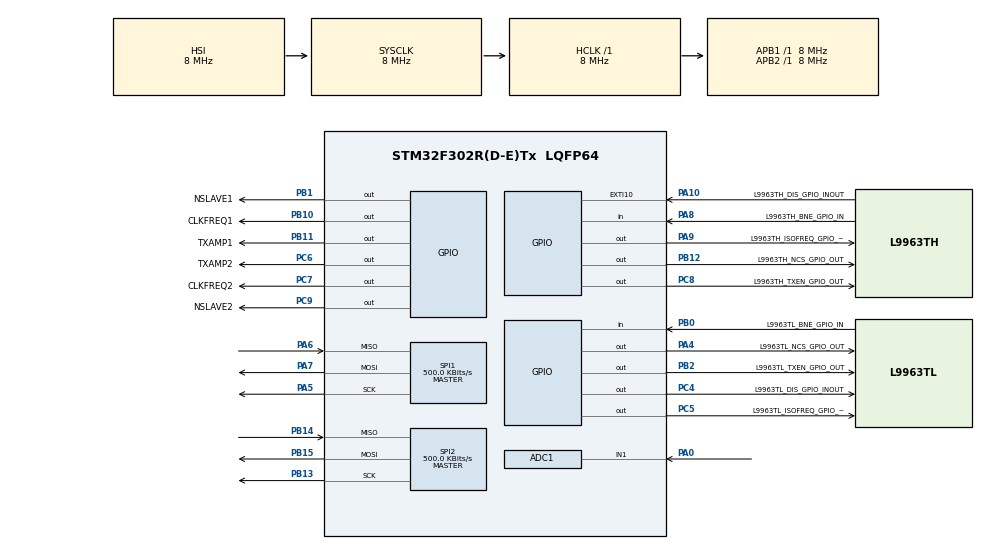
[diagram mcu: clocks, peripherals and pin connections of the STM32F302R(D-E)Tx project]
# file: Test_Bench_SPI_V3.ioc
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ADC1.Channel-0\#ChannelRegularConversion=ADC_CHANNEL_1
ADC1.NbrOfConversionFlag=1
ADC1.Offset-0\#ChannelRegularConversion=0
ADC1.OffsetNumber-0\#ChannelRegularConversion=ADC_OFFSET_NONE
ADC1.Rank-0\#ChannelRegularConversion=1
ADC1.SamplingTime-0\#ChannelRegularConversion=ADC_SAMPLETIME_1CYCLE_5
ADC1.SamplingTimeOPAMP-0\#ChannelRegularConversion=ADC_SAMPLETIME_4CYCLES_5
ADC1.master=1
Mcu.Family=STM32F3
Mcu.Name=STM32F302R(D-E)Tx
Mcu.Package=LQFP64
NVIC.PriorityGroup=NVIC_PRIORITYGROUP_4
PA0.Mode=IN1-Single-Ended
PA0.Signal=ADC1_IN1
PA10.GPIO_Label=L9963TH_DIS_GPIO_INOUT
PA10.Signal=GPXTI10
PA13.Mode=Serial_Wire
PA13.Signal=SYS_JTMS-SWDIO
PA14.Mode=Serial_Wire
PA14.Signal=SYS_JTCK-SWCLK
PA4.GPIO_Label=L9963TL_NCS_GPIO_OUT
PA4.Signal=GPIO_Output
PA5.Mode=Full_Duplex_Master
PA5.Signal=SPI1_SCK
PA6.Mode=Full_Duplex_Master
PA6.Signal=SPI1_MISO
PA7.Mode=Full_Duplex_Master
PA7.Signal=SPI1_MOSI
PA8.GPIO_Label=L9963TH_BNE_GPIO_IN
PA8.Signal=GPIO_Input
PA9.GPIO_Label=L9963TH_ISOFREQ_GPIO_OUT
PA9.Signal=GPIO_Output
PB0.GPIO_Label=L9963TL_BNE_GPIO_IN
PB0.Signal=GPIO_Input
PB1.GPIO_Label=NSLAVE1
PB1.Signal=GPIO_Output
PB10.GPIO_Label=CLKFREQ1
PB10.Signal=GPIO_Output
PB11.GPIO_Label=TXAMP1
PB11.Signal=GPIO_Output
PB12.GPIO_Label=L9963TH_NCS_GPIO_OUT
PB12.Signal=GPIO_Output
PB13.Mode=Full_Duplex_Master
PB13.Signal=SPI2_SCK
PB14.Mode=Full_Duplex_Master
PB14.Signal=SPI2_MISO
PB15.Mode=Full_Duplex_Master
PB15.Signal=SPI2_MOSI
PB2.GPIO_Label=L9963TL_TXEN_GPIO_OUT
PB2.Signal=GPIO_Output
PC4.GPIO_Label=L9963TL_DIS_GPIO_INOUT
PC4.Signal=GPIO_Output
PC5.GPIO_Label=L9963TL_ISOFREQ_GPIO_OUT
PC5.Signal=GPIO_Output
PC6.GPIO_Label=TXAMP2
PC6.Signal=GPIO_Output
PC7.GPIO_Label=CLKFREQ2
PC7.Signal=GPIO_Output
PC8.GPIO_Label=L9963TH_TXEN_GPIO_OUT
PC8.Signal=GPIO_Output
PC9.GPIO_Label=NSLAVE2
PC9.Signal=GPIO_Output
PF0-OSC_IN.Mode=HSE-External-Oscillator
PF0-OSC_IN.Signal=RCC_OSC_IN
PF1-OSC_OUT.Mode=HSE-External-Oscillator
PF1-OSC_OUT.Signal=RCC_OSC_OUT
ProjectManager.HeapSize=0x200
ProjectManager.StackSize=0x400
ProjectManager.TargetToolchain=STM32CubeIDE
RCC.AHBFreq_Value=8000000
RCC.APB1Freq_Value=8000000
RCC.APB2Freq_Value=8000000
RCC.CortexFreq_Value=8000000
RCC.HSE_VALUE=8000000
RCC.HSI_VALUE=8000000
RCC.LSE_VALUE=32768
RCC.PLLMUL=RCC_PLL_MUL4
RCC.SYSCLKFreq_VALUE=8000000
RCC.USBFreq_Value=16000000
SPI1.BaudRatePrescaler=SPI_BAUDRATEPRESCALER_16
SPI1.CalculateBaudRate=500.0 KBits/s
SPI1.DataSize=SPI_DATASIZE_8BIT
SPI1.Direction=SPI_DIRECTION_2LINES
SPI1.Mode=SPI_MODE_MASTER
SPI1.VirtualType=VM_MASTER
SPI2.BaudRatePrescaler=SPI_BAUDRATEPRESCALER_16
SPI2.CalculateBaudRate=500.0 KBits/s
SPI2.DataSize=SPI_DATASIZE_8BIT
SPI2.Direction=SPI_DIRECTION_2LINES
SPI2.Mode=SPI_MODE_MASTER
SPI2.VirtualType=VM_MASTER
board=custom

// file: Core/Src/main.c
/* USER CODE BEGIN Header */
/**
  ******************************************************************************
  * @file           : main.c
  * @brief          : Main program body
  ******************************************************************************
  * @attention
  *
  * Copyright (c) 2025 STMicroelectronics.
  * All rights reserved.
  *
  * This software is licensed under terms that can be found in the LICENSE file
  * in the root directory of this software component.
  * If no LICENSE file comes with this software, it is provided AS-IS.
  *
  ******************************************************************************
  */
/* USER CODE END Header */
#include "main.h"
#include "adc.h"
#include "spi.h"
#include "gpio.h"

/* USER CODE BEGIN Includes */
#include "L9963E.h"
#include "L9963_utils.h" // We will do this later its from their BMS code not their L9963e Library
/* USER CODE END Includes */

/* USER CODE BEGIN PTD */
L9963E_HandleTypeDef hl9963e;

/* USER CODE END PTD */

void SystemClock_Config(void);

int main(void)
{

  /* MCU Configuration--------------------------------------------------------*/

  /* Reset of all peripherals, Initializes the Flash interface and the Systick. */
  HAL_Init();

  /* USER CODE BEGIN Init */
  L9963E_utils_init();
  /* USER CODE END Init */

  /* Configure the system clock */
  SystemClock_Config();

  /* Initialize all configured peripherals */
  MX_GPIO_Init();
  MX_SPI1_Init();
  MX_SPI2_Init();
  MX_ADC1_Init();

  /* Infinite loop */
  /* USER CODE BEGIN WHILE */
  while (1)
  {
	  volatile float cell0_mv =  L9963E_utils_get_cell_mv(0, 0);

	  HAL_Delay(100);
    /* USER CODE END WHILE */

  }
}

void SystemClock_Config(void)
{
  RCC_OscInitTypeDef RCC_OscInitStruct = {0};
  RCC_ClkInitTypeDef RCC_ClkInitStruct = {0};
  RCC_PeriphCLKInitTypeDef PeriphClkInit = {0};

  /** Initializes the RCC Oscillators according to the specified parameters
  * in the RCC_OscInitTypeDef structure.
  */
  RCC_OscInitStruct.OscillatorType = RCC_OSCILLATORTYPE_HSI;
  RCC_OscInitStruct.HSIState = RCC_HSI_ON;
  RCC_OscInitStruct.HSICalibrationValue = RCC_HSICALIBRATION_DEFAULT;
  RCC_OscInitStruct.PLL.PLLState = RCC_PLL_ON;
  RCC_OscInitStruct.PLL.PLLSource = RCC_PLLSOURCE_HSI;
  RCC_OscInitStruct.PLL.PLLMUL = RCC_PLL_MUL4;
  RCC_OscInitStruct.PLL.PREDIV = RCC_PREDIV_DIV1;
  if (HAL_RCC_OscConfig(&RCC_OscInitStruct) != HAL_OK)
  {
    Error_Handler();
  }

  /** Initializes the CPU, AHB and APB buses clocks
  */
  RCC_ClkInitStruct.ClockType = RCC_CLOCKTYPE_HCLK|RCC_CLOCKTYPE_SYSCLK
                              |RCC_CLOCKTYPE_PCLK1|RCC_CLOCKTYPE_PCLK2;
  RCC_ClkInitStruct.SYSCLKSource = RCC_SYSCLKSOURCE_HSI;
  RCC_ClkInitStruct.AHBCLKDivider = RCC_SYSCLK_DIV1;
  RCC_ClkInitStruct.APB1CLKDivider = RCC_HCLK_DIV1;
  RCC_ClkInitStruct.APB2CLKDivider = RCC_HCLK_DIV1;

  if (HAL_RCC_ClockConfig(&RCC_ClkInitStruct, FLASH_LATENCY_0) != HAL_OK)
  {
    Error_Handler();
  }
  PeriphClkInit.PeriphClockSelection = RCC_PERIPHCLK_ADC12;
  PeriphClkInit.Adc12ClockSelection = RCC_ADC12PLLCLK_DIV1;
  if (HAL_RCCEx_PeriphCLKConfig(&PeriphClkInit) != HAL_OK)
  {
    Error_Handler();
  }
}

void Error_Handler(void)
{
  __disable_irq();
  while (1)
  {
  }
}
